VERSION ""
NS_ :

BS_:
BU_: MCU Dashboard

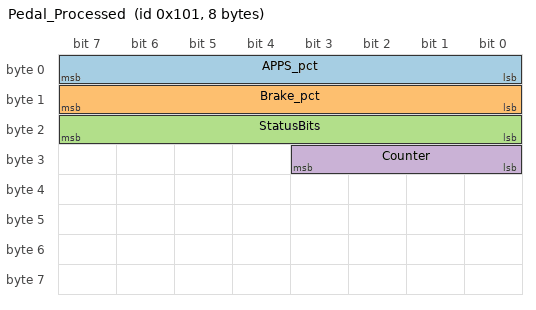
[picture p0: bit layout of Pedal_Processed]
BO_ 257 Pedal_Processed: 8 MCU
 SG_ APPS_pct : 0|8@1+ (100/255,0) [0|100] "%"  Dashboard
 SG_ Brake_pct : 8|8@1+ (100/255,0) [0|100] "%" Dashboard
 SG_ StatusBits : 16|8@1+ (1,0) [0|255] "" Dashboard
 SG_ Counter : 24|4@1+ (1,0) [0|15] "" Dashboard
